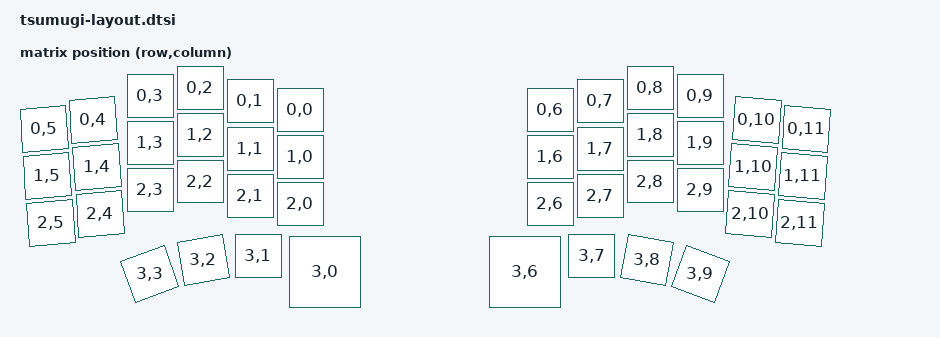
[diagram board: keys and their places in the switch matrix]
/* generated by keyboard/tools/gen_zmk_layout.py from the ergogen geometry - do not edit */

#include <physical_layouts.dtsi>
#include <dt-bindings/zmk/matrix_transform.h>

/ {
    tsumugi_transform: tsumugi_transform {
        compatible = "zmk,matrix-transform";
        columns = <12>;
        rows = <4>;
        map = <
            RC(0,5) RC(0,4) RC(0,3) RC(0,2) RC(0,1) RC(0,0) RC(0,6) RC(0,7) RC(0,8) RC(0,9) RC(0,10) RC(0,11)
            RC(1,5) RC(1,4) RC(1,3) RC(1,2) RC(1,1) RC(1,0) RC(1,6) RC(1,7) RC(1,8) RC(1,9) RC(1,10) RC(1,11)
            RC(2,5) RC(2,4) RC(2,3) RC(2,2) RC(2,1) RC(2,0) RC(2,6) RC(2,7) RC(2,8) RC(2,9) RC(2,10) RC(2,11)
            RC(3,3) RC(3,2) RC(3,1) RC(3,0) RC(3,6) RC(3,7) RC(3,8) RC(3,9)
        >;
    };

    tsumugi_layout: tsumugi_layout {
        compatible = "zmk,physical-layout";
        display-name = "Tsumugi 44";
        transform = <&tsumugi_transform>;
        kscan = <&kscan0>;
        //                        w    h     x     y       r    rx    ry
        keys
            = <&key_physical_attrs  100   94     0    86  (-400)    50   133>
            , <&key_physical_attrs  100   94    98    68  (-400)   148   115>
            , <&key_physical_attrs  100   94   212    19       0   262    66>
            , <&key_physical_attrs  100   94   312     3       0   362    50>
            , <&key_physical_attrs  100   94   412    30       0   462    77>
            , <&key_physical_attrs  100   94   512    47       0   562    94>
            , <&key_physical_attrs  100   94  1012    47       0  1062    94>
            , <&key_physical_attrs  100   94  1112    30       0  1162    77>
            , <&key_physical_attrs  100   94  1212     3       0  1262    50>
            , <&key_physical_attrs  100   94  1312    19       0  1362    66>
            , <&key_physical_attrs  100   94  1425    68     400  1475   115>
            , <&key_physical_attrs  100   94  1524    86     400  1574   133>
            , <&key_physical_attrs  100   94     6   180  (-400)    56   227>
            , <&key_physical_attrs  100   94   105   162  (-400)   155   209>
            , <&key_physical_attrs  100   94   212   114       0   262   161>
            , <&key_physical_attrs  100   94   312    97       0   362   144>
            , <&key_physical_attrs  100   94   412   125       0   462   172>
            , <&key_physical_attrs  100   94   512   141       0   562   188>
            , <&key_physical_attrs  100   94  1012   141       0  1062   188>
            , <&key_physical_attrs  100   94  1112   125       0  1162   172>
            , <&key_physical_attrs  100   94  1212    97       0  1262   144>
            , <&key_physical_attrs  100   94  1312   114       0  1362   161>
            , <&key_physical_attrs  100   94  1418   162     400  1468   209>
            , <&key_physical_attrs  100   94  1517   180     400  1567   227>
            , <&key_physical_attrs  100   94    13   274  (-400)    63   321>
            , <&key_physical_attrs  100   94   112   256  (-400)   162   303>
            , <&key_physical_attrs  100   94   212   208       0   262   255>
            , <&key_physical_attrs  100   94   312   191       0   362   238>
            , <&key_physical_attrs  100   94   412   219       0   462   266>
            , <&key_physical_attrs  100   94   512   236       0   562   283>
            , <&key_physical_attrs  100   94  1012   236       0  1062   283>
            , <&key_physical_attrs  100   94  1112   219       0  1162   266>
            , <&key_physical_attrs  100   94  1212   191       0  1262   238>
            , <&key_physical_attrs  100   94  1312   208       0  1362   255>
            , <&key_physical_attrs  100   94  1412   256     400  1462   303>
            , <&key_physical_attrs  100   94  1511   274     400  1561   321>
            , <&key_physical_attrs  100   94   211   376 (-2000)   261   423>
            , <&key_physical_attrs  100   94   318   348 (-1000)   368   395>
            , <&key_physical_attrs  100   94   428   339       0   478   386>
            , <&key_physical_attrs  150  150   537   344       0   612   419>
            , <&key_physical_attrs  150  150   937   344       0  1012   419>
            , <&key_physical_attrs  100   94  1095   339       0  1145   386>
            , <&key_physical_attrs  100   94  1205   348    1000  1255   395>
            , <&key_physical_attrs  100   94  1312   376    2000  1362   423>
            ;
    };
};
